# timers: IP-XACT component
VLNV spiritconsortium.org:Leon2RTL:timers:1.2

## Parameters
TPRESC = 22

## Bus interfaces (logical=physical port)
APBClk: slave spiritconsortium.org:busdef.clock:clock:1.0
  CLK=clk
APBReset: slave spiritconsortium.org:busdef.reset:reset:1.0
  RESETn=rst
ambaAPB: slave amba.com:AMBA2:APB:r2p0_4, memory map ambaAPB
  PSELx=psel, PENABLE=penable, PADDR=paddr, PWRITE=pwrite, PWDATA=pwdata, PRDATA=prdata, PCLK=clk, PRESETn=rst
Int0: master spiritconsortium.org:busdef.interrupt:interrupt:1.0
  IRQ=irq0
Int1: master spiritconsortium.org:busdef.interrupt:interrupt:1.0
  IRQ=irq1

## Ports
in clk
in rst
in psel
in penable
in paddr[31:0]
in pwrite
in pwdata[31:0]
out prdata[31:0]
out irq0
out irq1
out tick
out wdog
in dsuact
in ntrace
in freezetime
in lresp
in dresp
in dsuen
in dsubre

## Address spaces and blocks
ambaAPB.defaultid4489914: base 0, range 0x28, width 32

## Registers
Registers are 32-bit, read-write, no defined reset value unless marked. A register's access mark holds for its fields unless they carry their own. Offsets are from the block's base; lines under a group give offsets from that group; [hi:lo] are bit positions; {n}, {i} and the like mark numbered series; 'fields as' and 'values as' point back to an identical list; <NAME> marks a mode.

## ambaAPB.defaultid4489914
Base 0x00000000
0x00 timer1Counter — Timer 1 value
  [23:0] timer1Value — Value of Timer 1
0x04 timer1Reload — Timer 1 Reload Value
  [23:0] timerReloadValue
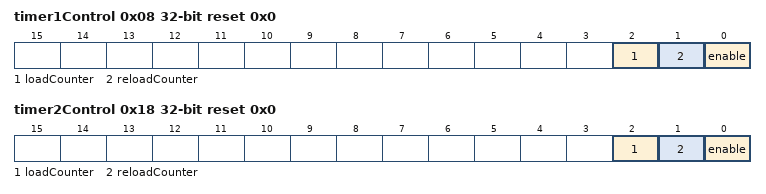
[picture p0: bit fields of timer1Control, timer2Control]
0x08 timer1Control reset 0x0 (reset mask 0x1)
  [2] loadCounter — When written with 1, will load the timer reload register into the timer counter register. Always reads as a 0.
  [1] reloadCounter — When set to 1 the counter will automatically be reloaded with the reload value after each underflow.
  [0] enable — Enables the timer when set.
0x0C watchdogCounter — Watchdog 1 value
  [23:0] watchdogValue
0x10 timer2Counter — Timer 2 value
  [23:0] timer2Value
0x14 timer2Reload — Timer 2 Reload Value
  [23:0] timerReloadValue
0x18 timer2Control reset 0x0 (reset mask 0x1)
  fields as timer1Control
0x20 prescalerCounter
  [9:0] reloadValue — Prescaler Counter Value
0x24 prescalerReloadValue
  [9:0] reloadValue

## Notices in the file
Copyright (c) 2006, 2008, 2009 The SPIRIT Consortium.
This work forms part of a deliverable of The SPIRIT Consortium.
Use of these materials are governed by the legal terms and conditions
outlined in the disclaimer available from www.spiritconsortium.org.
This source file is provided on an AS IS basis.  The SPIRIT
Consortium disclaims any warranty express or implied including
any warranty of merchantability and fitness for use for a
particular purpose.
The user of the source file shall indemnify and hold The SPIRIT
Consortium and its members harmless from any damages or liability.
